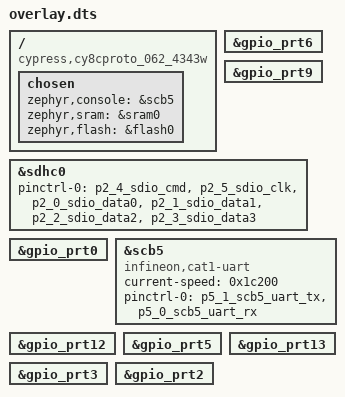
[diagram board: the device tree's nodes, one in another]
/ {
	compatible = "cypress,cy8cproto_062_4343w", "cypress,PSoC6";
	chosen {
		zephyr,console = &scb5;
		zephyr,sram = &sram0;
		zephyr,flash = &flash0;
	};
};
&gpio_prt6{
	status = "okay";
};
&gpio_prt9{
	status = "okay";
};
&sdhc0{
	status = "okay";
	pinctrl-0 = < &p2_4_sdio_cmd &p2_5_sdio_clk &p2_0_sdio_data0 &p2_1_sdio_data1 &p2_2_sdio_data2 &p2_3_sdio_data3 >;
	pinctrl-names = "default";
};
&gpio_prt0{
	status = "okay";
};
&scb5{
	compatible = "infineon,cat1-uart";
	status = "okay";
	current-speed = < 0x1c200 >;
	pinctrl-0 = < &p5_1_scb5_uart_tx &p5_0_scb5_uart_rx >;
	pinctrl-names = "default";
};
&gpio_prt12{
	status = "okay";
};
&gpio_prt5{
	status = "okay";
};
&gpio_prt13{
	status = "okay";
};
&gpio_prt3{
	status = "okay";
};
&gpio_prt2{
	status = "okay";
};
